# ATSAMD20J15B register map
Vendor: Microchip Technology Inc.; Series: SAMD20; File version: G
CPU: CM0+ r0p1, little endian, no MPU, no FPU, VTOR, 2 interrupt priority bits, 25 interrupts
Registers are 8-bit, read-write, reset 0x0 unless marked. A register's access mark holds for its fields unless they carry their own. Offsets are from the block's base; [hi:lo] are bit positions; lines under a group give offsets from that group; {n}, {i} and the like mark numbered series; 'fields as' and 'values as' point back to an identical list.

## SERCOM0 — Serial Communication Interface 0
Base 0x42000800; register names take the prefix SERCOM_
Same registers: SERCOM1 0x42000C00, SERCOM2 0x42001000, SERCOM3 0x42001400, SERCOM4 0x42001800, SERCOM5 0x42001C00
0x00 I2CM group — I2C Master Mode
  0x00 CTRLA 32-bit — I2CM Control A
    [30] LOWTOUT — SCL Low Time-out
    [29:28] INACTOUT — Inactive Time-out
    [21:20] SDAHOLD — SDA Hold Time
    [16] PINOUT — Pin Usage
    [7] RUNSTDBY — Run in Standby
    [4:2] MODE — Operating Mode
      0=USART_EXT_CLK (USART mode with external clock); 1=USART_INT_CLK (USART mode with internal clock); 2=SPI_SLAVE (SPI mode with external clock); 3=SPI_MASTER (SPI mode with internal clock); 4=I2C_SLAVE (I2C mode with external clock); 5=I2C_MASTER (I2C mode with internal clock)
    [1] ENABLE
    [0] SWRST — Software Reset
  0x04 CTRLB 32-bit — I2CM Control B
    [18] ACKACT — Acknowledge Action
    [17:16] CMD wo — Command
    [9] QCEN — Quick Command Enable
    [8] SMEN — Smart Mode Enable
  0x08 DBGCTRL — I2CM Debug Control
    [0] DBGSTOP — Debug Stop Mode
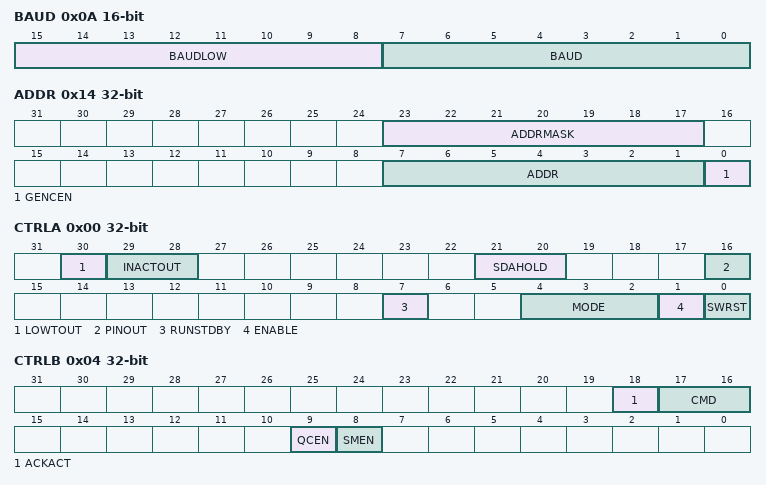
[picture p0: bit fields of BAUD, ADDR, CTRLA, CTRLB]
  0x0A BAUD 16-bit — I2CM Baud Rate
    [15:8] BAUDLOW — Master Baud Rate Low
    [7:0] BAUD — Master Baud Rate
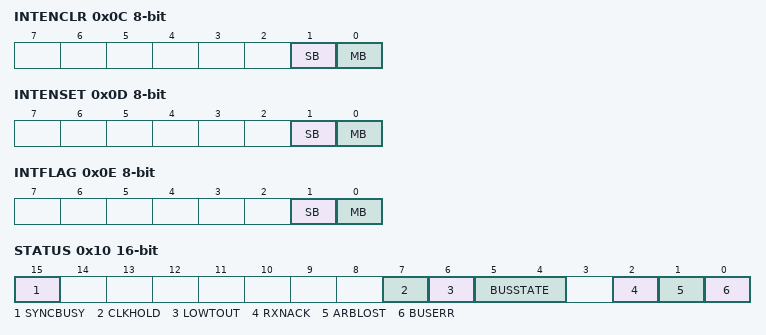
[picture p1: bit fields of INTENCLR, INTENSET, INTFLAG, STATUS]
  0x0C INTENCLR — I2CM Interrupt Enable Clear
    [1] SB — Slave on Bus Interrupt Enable
    [0] MB — Master on Bus Interrupt Enable
  0x0D INTENSET — I2CM Interrupt Enable Set
    fields as I2CM.INTENCLR
  0x0E INTFLAG — I2CM Interrupt Flag Status and Clear
    [1] SB — Slave on Bus
    [0] MB — Master on Bus
  0x10 STATUS 16-bit — I2CM Status
    [15] SYNCBUSY ro — Synchronization Busy
    [7] CLKHOLD — Clock Hold
    [6] LOWTOUT — SCL Low Time-out
    [5:4] BUSSTATE
    [2] RXNACK ro — Received Not Acknowledge
    [1] ARBLOST — Arbitration Lost
    [0] BUSERR — Bus Error
  0x14 ADDR — I2CM Address
    [7:0] ADDR — Address
  0x18 DATA — I2CM Data
0x00 I2CS group (alternate view of I2CM) — I2C Slave Mode
  0x00 CTRLA 32-bit — I2CS Control A
    [30] LOWTOUT — SCL Low Time-out
    [21:20] SDAHOLD — SDA Hold Time
      0=DIS (Disabled); 1=50-100 ns hold time; 2=300-600 ns hold time; 3=400-800 ns hold time
    [16] PINOUT — Pin Usage
    [7] RUNSTDBY — Run in Standby
    [4:2] MODE — Operating Mode
      values as I2CM.CTRLA.MODE
    [1] ENABLE
    [0] SWRST — Software Reset
  0x04 CTRLB 32-bit — I2CS Control B
    [18] ACKACT — Acknowledge Action
    [17:16] CMD wo — Command
    [15:14] AMODE — Address Mode
    [8] SMEN — Smart Mode Enable
  0x0C INTENCLR — I2CS Interrupt Enable Clear
    [2] DRDY — Data Ready Interrupt Enable
    [1] AMATCH — Address Match Interrupt Enable
    [0] PREC — Stop Received Interrupt Enable
  0x0D INTENSET — I2CS Interrupt Enable Set
    fields as I2CS.INTENCLR
  0x0E INTFLAG — I2CS Interrupt Flag Status and Clear
    [2] DRDY — Data Ready
    [1] AMATCH — Address Match
    [0] PREC — Stop Received
  0x10 STATUS 16-bit — I2CS Status
    [15] SYNCBUSY ro — Synchronization Busy
    [7] CLKHOLD ro — Clock Hold
    [6] LOWTOUT — SCL Low Time-out
    [4] SR ro — Repeated Start
    [3] DIR ro — Read / Write Direction
    [2] RXNACK ro — Received Not Acknowledge
    [1] COLL — Transmit Collision
    [0] BUSERR — Bus Error
  0x14 ADDR 32-bit — I2CS Address
    [23:17] ADDRMASK — Address Mask
    [7:1] ADDR — Address
    [0] GENCEN — General Call Address Enable
  0x18 DATA — I2CS Data
0x00 SPI group (alternate view of I2CM) — SPI Mode
  0x00 CTRLA 32-bit — SPI Control A
    [30] DORD — Data Order
    [29] CPOL — Clock Polarity
    [28] CPHA — Clock Phase
    [27:24] FORM — Frame Format
      0=SPI (SPI frame); 2=SPI_ADDR (SPI frame with address)
    [21:20] DIPO — Data In Pinout
    [17:16] DOPO — Data Out Pinout
    [8] IBON — Immediate Buffer Overflow Notification
    [7] RUNSTDBY — Run In Standby
    [4:2] MODE — Operating Mode
      values as I2CM.CTRLA.MODE
    [1] ENABLE
    [0] SWRST — Software Reset
  0x04 CTRLB 32-bit — SPI Control B
    [17] RXEN — Receiver Enable
    [15:14] AMODE — Address Mode
      0=MASK (ADDRMASK is used as a mask to the ADDR register.); 1=2ADDR (The slave responds to the 2 unique addresses in ADDR and ADDRMASK.); 2=RANGE (The slave responds to the range of addresses between and including ADDR and ADDRMASK. ADDR is the upper limit.)
    [6] PLOADEN — Slave Data Preload Enable
    [2:0] CHSIZE — Character Size
  0x08 DBGCTRL — SPI Debug Control
    [0] DBGSTOP — Debug Stop Mode
  0x0A BAUD — SPI Baud Rate
  0x0C INTENCLR — SPI Interrupt Enable Clear
    [2] RXC — Receive Complete Interrupt Enable
    [1] TXC — Transmit Complete Interrupt Enable
    [0] DRE — Data Register Empty Interrupt Enable
  0x0D INTENSET — SPI Interrupt Enable Set
    fields as SPI.INTENCLR
  0x0E INTFLAG — SPI Interrupt Flag Status and Clear
    [2] RXC ro — Receive Complete
    [1] TXC — Transmit Complete
    [0] DRE ro — Data Register Empty
  0x10 STATUS 16-bit — SPI Status
    [15] SYNCBUSY ro — Synchronization Busy
    [2] BUFOVF — Buffer Overflow
  0x14 ADDR 32-bit — SPI Address
    [23:16] ADDRMASK — Address Mask
    [7:0] ADDR — Address
  0x18 DATA 16-bit — SPI Data
    [8:0] DATA
0x00 USART group (alternate view of I2CM) — USART Mode
  0x00 CTRLA 32-bit — USART Control A
    [30] DORD — Data Order
    [29] CPOL — Clock Polarity
    [28] CMODE — Communication Mode
    [27:24] FORM — Frame Format
      0=USART frame; 1=USART frame with parity
    [21:20] RXPO — Receive Data Pinout
      {v}=PAD{v} (SERCOM_PAD{v}) (v=0..3)
    [16] TXPO — Transmit Data Pinout
      0=PAD0 (TXD at PAD0, XCK at PAD1); 1=PAD2 (TXD at PAD2, XCK at PAD3)
    [8] IBON — Immediate Buffer Overflow Notification
    [7] RUNSTDBY — Run In Standby
    [4:2] MODE — Operating Mode
      values as I2CM.CTRLA.MODE
    [1] ENABLE
    [0] SWRST — Software Reset
  0x04 CTRLB 32-bit — USART Control B
    [17] RXEN — Receiver Enable
    [16] TXEN — Transmitter Enable
    [13] PMODE — Parity Mode
    [9] SFDE — Start of Frame Detection Enable
    [6] SBMODE — Stop Bit Mode
    [2:0] CHSIZE — Character Size
  0x08 DBGCTRL — USART Debug Control
    [0] DBGSTOP — Debug Stop Mode
  0x0A BAUD 16-bit — USART Baud
    [15:0] BAUD — Baud Value
  0x0C INTENCLR — USART Interrupt Enable Clear
    [3] RXS — Receive Start Interrupt Disable
    [2] RXC — Receive Complete Interrupt Enable
    [1] TXC — Transmit Complete Interrupt Enable
    [0] DRE — Data Register Empty Interrupt Enable
  0x0D INTENSET — USART Interrupt Enable Set
    [3] RXS — Receive Start Interrupt Enable
    [2] RXC — Receive Complete Interrupt Enable
    [1] TXC — Transmit Complete Interrupt Enable
    [0] DRE — Data Register Empty Interrupt Enable
  0x0E INTFLAG — USART Interrupt Flag Status and Clear
    [3] RXS wo — Receive Start Interrupt
    [2] RXC ro — Receive Complete
    [1] TXC — Transmit Complete
    [0] DRE ro — Data Register Empty
  0x10 STATUS 16-bit — USART Status
    [15] SYNCBUSY ro — Synchronization Busy
    [2] BUFOVF — Buffer Overflow
    [1] FERR — Frame Error
    [0] PERR — Parity Error
  0x18 DATA 16-bit — USART Data
    [8:0] DATA

## Notices in the file
Copyright (c) 2018 Microchip Technology Inc.
SPDX-License-Identifier: Apache-2.0
Licensed under the Apache License, Version 2.0 (the "License");
you may not use this file except in compliance with the License.
You may obtain a copy of the License at
http://www.apache.org/licenses/LICENSE-2.0
Unless required by applicable law or agreed to in writing, software
distributed under the License is distributed on an "AS IS" BASIS,
WITHOUT WARRANTIES OR CONDITIONS OF ANY KIND, either express or implied.
See the License for the specific language governing permissions and
limitations under the License.
